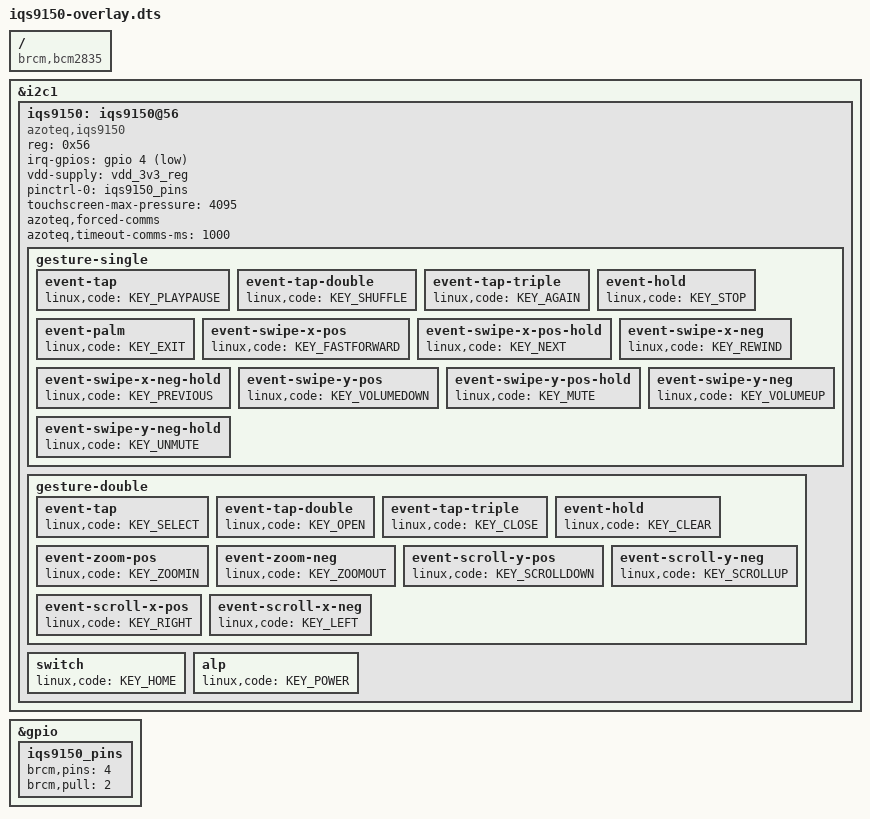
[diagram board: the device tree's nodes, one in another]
// SPDX-License-Identifier: GPL-2.0-or-later
// Definitions for Azoteq IQS9150 trackpad controller
/dts-v1/;
/plugin/;
#include <dt-bindings/gpio/gpio.h>
#include <dt-bindings/input/input.h>

/ {
	compatible = "brcm,bcm2835";

	fragment@0 {
		target = <&i2c1>;
		__overlay__ {
			#address-cells = <1>;
			#size-cells = <0>;
			status = "okay";

			iqs9150: iqs9150@56 {
				compatible = "azoteq,iqs9150";
				reg = <0x56>;
				irq-gpios = <&gpio 4 GPIO_ACTIVE_LOW>;
				vdd-supply = <&vdd_3v3_reg>;
				pinctrl-names = "default";
				pinctrl-0 = <&iqs9150_pins>;
				touchscreen-max-pressure = <4095>;
				azoteq,forced-comms;
				azoteq,timeout-comms-ms = <1000>;

				gesture-single {
					event-tap {
						linux,code = <KEY_PLAYPAUSE>;
					};

					event-tap-double {
						linux,code = <KEY_SHUFFLE>;
					};

					event-tap-triple {
						linux,code = <KEY_AGAIN>;
					};

					event-hold {
						linux,code = <KEY_STOP>;
					};

					event-palm {
						linux,code = <KEY_EXIT>;
					};

					event-swipe-x-pos {
						linux,code = <KEY_FASTFORWARD>;
					};

					event-swipe-x-pos-hold {
						linux,code = <KEY_NEXT>;
					};

					event-swipe-x-neg {
						linux,code = <KEY_REWIND>;
					};

					event-swipe-x-neg-hold {
						linux,code = <KEY_PREVIOUS>;
					};

					event-swipe-y-pos {
						linux,code = <KEY_VOLUMEDOWN>;
					};

					event-swipe-y-pos-hold {
						linux,code = <KEY_MUTE>;
					};

					event-swipe-y-neg {
						linux,code = <KEY_VOLUMEUP>;
					};

					event-swipe-y-neg-hold {
						linux,code = <KEY_UNMUTE>;
					};
				};

				gesture-double {
					event-tap {
						linux,code = <KEY_SELECT>;
					};

					event-tap-double {
						linux,code = <KEY_OPEN>;
					};

					event-tap-triple {
						linux,code = <KEY_CLOSE>;
					};

					event-hold {
						linux,code = <KEY_CLEAR>;
					};

					event-zoom-pos {
						linux,code = <KEY_ZOOMIN>;
					};

					event-zoom-neg {
						linux,code = <KEY_ZOOMOUT>;
					};

					event-scroll-y-pos {
						linux,code = <KEY_SCROLLDOWN>;
					};

					event-scroll-y-neg {
						linux,code = <KEY_SCROLLUP>;
					};

					event-scroll-x-pos {
						linux,code = <KEY_RIGHT>;
					};

					event-scroll-x-neg {
						linux,code = <KEY_LEFT>;
					};
				};

				switch {
					linux,code = <KEY_HOME>;
				};

				alp {
					linux,code = <KEY_POWER>;
				};
			};
		};
	};

	fragment@1 {
		target = <&iqs9150>;
		iqs9150_reset: __dormant__ {
			reset-gpios = <&gpio 255 (GPIO_ACTIVE_LOW |
						  GPIO_PUSH_PULL)>;
		};
	};

	fragment@2 {
		target = <&gpio>;
		__overlay__ {
			iqs9150_pins: iqs9150_pins {
				brcm,pins = <4>;
				brcm,pull = <2>;
			};
		};
	};

	__overrides__ {
		interrupt = <&iqs9150>,"irq-gpios:4",
			    <&iqs9150_pins>,"brcm,pins:0";
		reset = <0>,"+1", <&iqs9150_reset>,"reset-gpios:4";
		sizex = <&iqs9150>,"touchscreen-size-x:0";
		sizey = <&iqs9150>,"touchscreen-size-y:0";
		invx = <&iqs9150>,"touchscreen-inverted-x?";
		invy = <&iqs9150>,"touchscreen-inverted-y?";
		swapxy = <&iqs9150>,"touchscreen-swapped-x-y?";
	};
};
